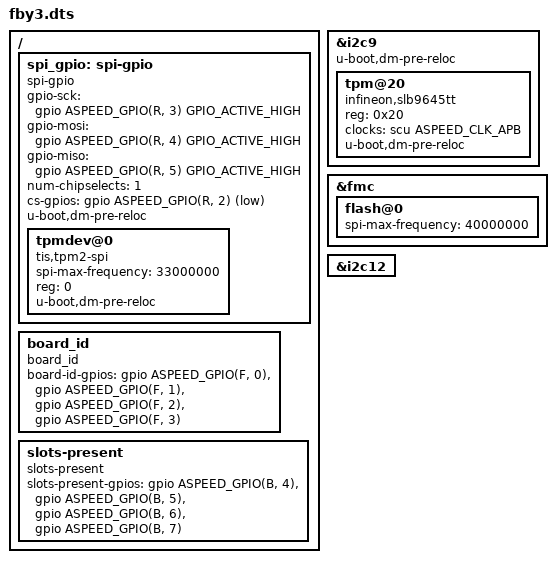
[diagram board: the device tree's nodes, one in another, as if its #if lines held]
/dts-v1/;

#if CONFIG_IS_ENABLED(PFR_SUPPORT)
#include "ast2500-fb-pfr.dtsi"
#else
#include "ast2500-fb-vboot.dtsi"
#endif

#if CONFIG_IS_ENABLED(TPM_V1)
&i2c9 {
	status = "okay";
	u-boot,dm-pre-reloc;
	tpm@20 {
		/* Emulators should use atmel,at97sc3204t. */
		compatible = "infineon,slb9645tt";
		reg = <0x20>;
		clocks = <&scu ASPEED_CLK_APB>;
		u-boot,dm-pre-reloc;
	};
};
#endif

#if CONFIG_IS_ENABLED(TPM_V2)
#include <dt-bindings/gpio/aspeed-gpio.h>
/ {
	spi_gpio: spi-gpio {
		status = "okay";
		compatible = "spi-gpio";
		#address-cells = <1>;
		#size-cells = <0>;

		gpio-sck = <&gpio ASPEED_GPIO(R, 3) GPIO_ACTIVE_HIGH>;
		gpio-mosi = <&gpio ASPEED_GPIO(R, 4) GPIO_ACTIVE_HIGH>;
		gpio-miso = <&gpio ASPEED_GPIO(R, 5) GPIO_ACTIVE_HIGH>;
		num-chipselects = <1>;
		cs-gpios = <&gpio ASPEED_GPIO(R, 2) GPIO_ACTIVE_LOW>;
		u-boot,dm-pre-reloc;

		tpmdev@0 {
			compatible = "tis,tpm2-spi";
			spi-max-frequency = <33000000>;
			reg = <0>;
			u-boot,dm-pre-reloc;
		};
	};
};

#endif

&fmc {
	flash@0 {
		spi-max-frequency = <40000000>;
	};
};

&i2c12 {
	status = "okay";
	/* baseboard CPLD */
};

#include <dt-bindings/gpio/aspeed-gpio.h>
/ {
	board_id {
		compatible = "board_id";
		board-id-gpios = <&gpio ASPEED_GPIO(F, 0) GPIO_ACTIVE_HIGH>,
		                 <&gpio ASPEED_GPIO(F, 1) GPIO_ACTIVE_HIGH>,
		                 <&gpio ASPEED_GPIO(F, 2) GPIO_ACTIVE_HIGH>,
		                 <&gpio ASPEED_GPIO(F, 3) GPIO_ACTIVE_HIGH>;
	};
	slots-present {
		compatible = "slots-present";
		slots-present-gpios = <&gpio ASPEED_GPIO(B, 4) GPIO_ACTIVE_HIGH>,
		                      <&gpio ASPEED_GPIO(B, 5) GPIO_ACTIVE_HIGH>,
		                      <&gpio ASPEED_GPIO(B, 6) GPIO_ACTIVE_HIGH>,
		                      <&gpio ASPEED_GPIO(B, 7) GPIO_ACTIVE_HIGH>;
	};
};
